# DEBUGSS0_DEBUG_CELL_ROM_SLV register map
Vendor: Texas Instruments
Peripheral module from a debugger description file (folder am62P).
Registers are 32-bit, read-only, reset values left out (the file's numbers can be read two ways) unless marked. A register's access mark holds for its fields unless they carry their own. Offsets are as the file gives them; lines under a group give offsets from that group; [hi:lo] are bit positions; {n}, {i} and the like mark numbered series; 'fields as' and 'values as' point back to an identical list; <NAME> marks a mode.

## DEBUGSS0_DEBUG_CELL_ROM_SLV
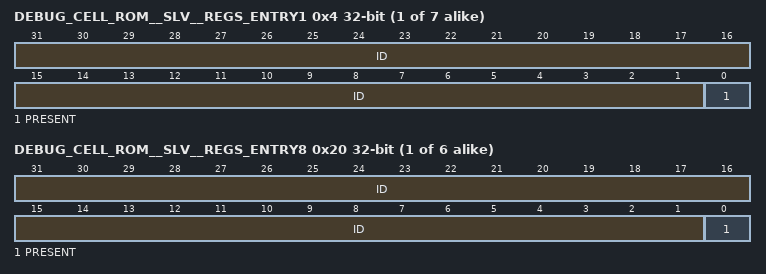
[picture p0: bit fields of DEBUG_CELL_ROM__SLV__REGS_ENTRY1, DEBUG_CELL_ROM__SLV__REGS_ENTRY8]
{0x0+4i} DEBUG_CELL_ROM__SLV__REGS_ENTRY{i} (i=1..7)
  [31:1] ID — 4kB - MSMCv3 CSCTI Instance {i}
  [0] PRESENT — Component present,1, or not present,0, status bit
{0x0+4i} DEBUG_CELL_ROM__SLV__REGS_ENTRY{i} (i=8..13)
  [31:1] ID — 256kB - Processor Cluster Instance {i-8}
  [0] PRESENT — Component present,1, or not present,0, status bit
0x50 DEBUG_CELL_ROM__SLV__REGS_ENTRY14
  [31:0] ID — End of table
{0xFC0+4i} DEBUG_CELL_ROM__SLV__REGS_PERIPHID{i} (i=4..7)
  [31:0] ID — Peripheral Identification Number
{0xFE0+4i} DEBUG_CELL_ROM__SLV__REGS_PERIPHID{i} (i=0..3)
  [31:0] ID — Peripheral Identification Number
{0xFF0+4i} DEBUG_CELL_ROM__SLV__REGS_COMPONENTID{i} (i=0..3)
  [31:0] ID — Component Identification Number
